AUTOSAR XML (schema 4.0)
package /Body_Components
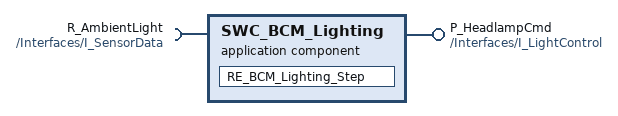
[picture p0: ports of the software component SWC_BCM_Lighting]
  application sw component type SWC_BCM_Lighting  # Body Control Module Lighting Controller
    provide port P_HeadlampCmd: provided-interface=/Interfaces/I_LightControl
    require port R_AmbientLight: required-interface=/Interfaces/I_SensorData
    behavior SWC_BCM_Lighting_Behavior
      runnable RE_BCM_Lighting_Step: symbol=BCM_Lighting_Step
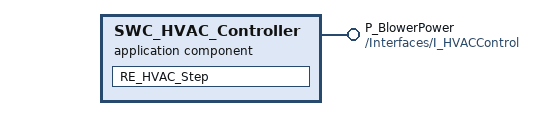
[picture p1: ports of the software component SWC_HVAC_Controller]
  application sw component type SWC_HVAC_Controller  # Cabin HVAC and Climate Controller
    provide port P_BlowerPower: provided-interface=/Interfaces/I_HVACControl
    behavior SWC_HVAC_Behavior
      runnable RE_HVAC_Step: symbol=HVAC_Step
